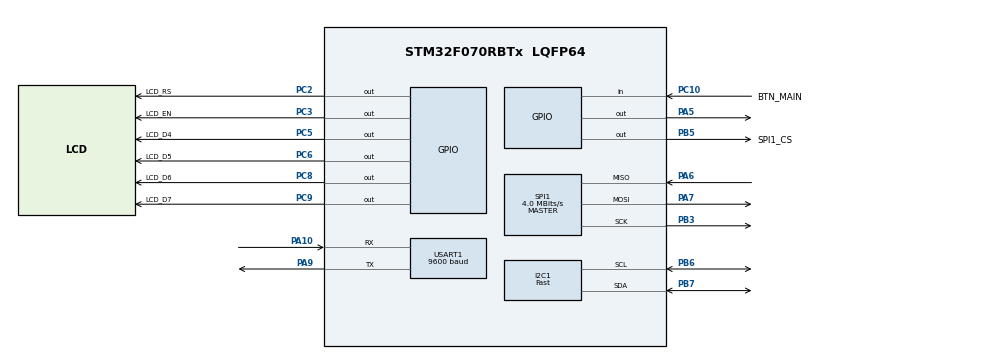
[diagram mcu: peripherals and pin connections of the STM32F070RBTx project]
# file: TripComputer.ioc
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Dma.Request0=USART1_RX
Dma.USART1_RX.0.Direction=DMA_PERIPH_TO_MEMORY
Dma.USART1_RX.0.Instance=DMA1_Channel3
Dma.USART1_RX.0.MemDataAlignment=DMA_MDATAALIGN_BYTE
Dma.USART1_RX.0.MemInc=DMA_MINC_ENABLE
Dma.USART1_RX.0.Mode=DMA_CIRCULAR
Dma.USART1_RX.0.PeriphDataAlignment=DMA_PDATAALIGN_BYTE
Dma.USART1_RX.0.PeriphInc=DMA_PINC_DISABLE
Dma.USART1_RX.0.Priority=DMA_PRIORITY_HIGH
FREERTOS.Tasks01=defaultTask,24,128,StartDefaultTask,Default,NULL,Dynamic,NULL,NULL
FREERTOS.configCHECK_FOR_STACK_OVERFLOW=2
I2C1.I2C_Speed_Mode=I2C_Fast
I2C1.Timing=0x0010020A
Mcu.Family=STM32F0
Mcu.Name=STM32F070RBTx
Mcu.Package=LQFP64
NVIC.DMA1_Channel2_3_IRQn=true\:3\:0\:false\:false\:true\:true\:false\:true\:true
NVIC.TIM1_BRK_UP_TRG_COM_IRQn=true\:3\:0\:false\:false\:true\:false\:false\:true\:true
NVIC.TimeBase=TIM1_BRK_UP_TRG_COM_IRQn
NVIC.TimeBaseIP=TIM1
NVIC.USART1_IRQn=true\:3\:0\:false\:false\:true\:true\:true\:true\:true
PA10.Mode=Asynchronous
PA10.Signal=USART1_RX
PA13.Mode=Serial_Wire
PA13.Signal=SYS_SWDIO
PA14.Mode=Serial_Wire
PA14.Signal=SYS_SWCLK
PA5.Signal=GPIO_Output
PA6.Mode=Full_Duplex_Master
PA6.Signal=SPI1_MISO
PA7.Mode=Full_Duplex_Master
PA7.Signal=SPI1_MOSI
PA9.Mode=Asynchronous
PA9.Signal=USART1_TX
PB3.Mode=Full_Duplex_Master
PB3.Signal=SPI1_SCK
PB5.GPIO_Label=SPI1_CS
PB5.Signal=GPIO_Output
PB6.Mode=I2C
PB6.Signal=I2C1_SCL
PB7.Mode=I2C
PB7.Signal=I2C1_SDA
PC10.GPIO_Label=BTN_MAIN
PC10.GPIO_PuPd=GPIO_PULLUP
PC10.Signal=GPIO_Input
PC2.GPIO_Label=LCD_RS
PC2.Signal=GPIO_Output
PC3.GPIO_Label=LCD_EN
PC3.Signal=GPIO_Output
PC5.GPIO_Label=LCD_D4
PC5.Signal=GPIO_Output
PC6.GPIO_Label=LCD_D5
PC6.Signal=GPIO_Output
PC8.GPIO_Label=LCD_D6
PC8.Signal=GPIO_Output
PC9.GPIO_Label=LCD_D7
PC9.Signal=GPIO_Output
ProjectManager.HeapSize=0x200
ProjectManager.StackSize=0x400
ProjectManager.TargetToolchain=CMake
SPI1.CalculateBaudRate=4.0 MBits/s
SPI1.Direction=SPI_DIRECTION_2LINES
SPI1.Mode=SPI_MODE_MASTER
SPI1.VirtualType=VM_MASTER
USART1.BaudRate=9600
USART1.VirtualMode-Asynchronous=VM_ASYNC
VP_FATFS_VS_Generic.Mode=User_defined
VP_FREERTOS_VS_CMSIS_V2.Mode=CMSIS_V2
VP_SYS_VS_tim1.Mode=TIM1
board=custom

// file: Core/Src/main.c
/* USER CODE BEGIN Header */
/**
  ******************************************************************************
  * @file           : main.c
  * @brief          : Main program body
  ******************************************************************************
  * @attention
  *
  * Copyright (c) 2026 STMicroelectronics.
  * All rights reserved.
  *
  * This software is licensed under terms that can be found in the LICENSE file
  * in the root directory of this software component.
  * If no LICENSE file comes with this software, it is provided AS-IS.
  *
  ******************************************************************************
  */
/* USER CODE END Header */
#include "main.h"
#include "cmsis_os.h"
#include "fatfs.h"

/* USER CODE BEGIN Includes */
#include "App.h"
/* USER CODE END Includes */

I2C_HandleTypeDef hi2c1;

SPI_HandleTypeDef hspi1;

UART_HandleTypeDef huart1;
DMA_HandleTypeDef hdma_usart1_rx;

/* Definitions for defaultTask */
osThreadId_t defaultTaskHandle;
const osThreadAttr_t defaultTask_attributes = {
  .name = "defaultTask",
  .stack_size = 128 * 4,
  .priority = (osPriority_t) osPriorityNormal,
};

void SystemClock_Config(void);
static void MX_GPIO_Init(void);
static void MX_DMA_Init(void);
static void MX_USART1_UART_Init(void);
static void MX_I2C1_Init(void);
static void MX_SPI1_Init(void);
void StartDefaultTask(void *argument);

int main(void)
{

  /* MCU Configuration--------------------------------------------------------*/

  /* Reset of all peripherals, Initializes the Flash interface and the Systick. */
  HAL_Init();

  /* Configure the system clock */
  SystemClock_Config();

  /* Initialize all configured peripherals */
  MX_GPIO_Init();
  MX_DMA_Init();
  MX_USART1_UART_Init();
  MX_I2C1_Init();
  MX_SPI1_Init();
  MX_FATFS_Init();
  /* USER CODE BEGIN 2 */
  App_Main();
  /* USER CODE END 2 */

  /* Init scheduler */
  osKernelInitialize();

  /* Create the thread(s) */
  /* creation of defaultTask */
  defaultTaskHandle = osThreadNew(StartDefaultTask, NULL, &defaultTask_attributes);

  /* Start scheduler */
  osKernelStart();

  /* We should never get here as control is now taken by the scheduler */

  /* Infinite loop */
  while (1)
  {

  }
}

void SystemClock_Config(void)
{
  RCC_OscInitTypeDef RCC_OscInitStruct = {0};
  RCC_ClkInitTypeDef RCC_ClkInitStruct = {0};
  RCC_PeriphCLKInitTypeDef PeriphClkInit = {0};

  /** Initializes the RCC Oscillators according to the specified parameters
  * in the RCC_OscInitTypeDef structure.
  */
  RCC_OscInitStruct.OscillatorType = RCC_OSCILLATORTYPE_HSI;
  RCC_OscInitStruct.HSIState = RCC_HSI_ON;
  RCC_OscInitStruct.HSICalibrationValue = RCC_HSICALIBRATION_DEFAULT;
  RCC_OscInitStruct.PLL.PLLState = RCC_PLL_NONE;
  if (HAL_RCC_OscConfig(&RCC_OscInitStruct) != HAL_OK)
  {
    Error_Handler();
  }

  /** Initializes the CPU, AHB and APB buses clocks
  */
  RCC_ClkInitStruct.ClockType = RCC_CLOCKTYPE_HCLK|RCC_CLOCKTYPE_SYSCLK
                              |RCC_CLOCKTYPE_PCLK1;
  RCC_ClkInitStruct.SYSCLKSource = RCC_SYSCLKSOURCE_HSI;
  RCC_ClkInitStruct.AHBCLKDivider = RCC_SYSCLK_DIV1;
  RCC_ClkInitStruct.APB1CLKDivider = RCC_HCLK_DIV1;

  if (HAL_RCC_ClockConfig(&RCC_ClkInitStruct, FLASH_LATENCY_0) != HAL_OK)
  {
    Error_Handler();
  }
  PeriphClkInit.PeriphClockSelection = RCC_PERIPHCLK_USART1|RCC_PERIPHCLK_I2C1;
  PeriphClkInit.Usart1ClockSelection = RCC_USART1CLKSOURCE_PCLK1;
  PeriphClkInit.I2c1ClockSelection = RCC_I2C1CLKSOURCE_HSI;
  if (HAL_RCCEx_PeriphCLKConfig(&PeriphClkInit) != HAL_OK)
  {
    Error_Handler();
  }
}

static void MX_I2C1_Init(void)
{

  hi2c1.Instance = I2C1;
  hi2c1.Init.Timing = 0x0010020A;
  hi2c1.Init.OwnAddress1 = 0;
  hi2c1.Init.AddressingMode = I2C_ADDRESSINGMODE_7BIT;
  hi2c1.Init.DualAddressMode = I2C_DUALADDRESS_DISABLE;
  hi2c1.Init.OwnAddress2 = 0;
  hi2c1.Init.OwnAddress2Masks = I2C_OA2_NOMASK;
  hi2c1.Init.GeneralCallMode = I2C_GENERALCALL_DISABLE;
  hi2c1.Init.NoStretchMode = I2C_NOSTRETCH_DISABLE;
  if (HAL_I2C_Init(&hi2c1) != HAL_OK)
  {
    Error_Handler();
  }

  /** Configure Analogue filter
  */
  if (HAL_I2CEx_ConfigAnalogFilter(&hi2c1, I2C_ANALOGFILTER_ENABLE) != HAL_OK)
  {
    Error_Handler();
  }

  /** Configure Digital filter
  */
  if (HAL_I2CEx_ConfigDigitalFilter(&hi2c1, 0) != HAL_OK)
  {
    Error_Handler();
  }

}

static void MX_SPI1_Init(void)
{

  /* SPI1 parameter configuration*/
  hspi1.Instance = SPI1;
  hspi1.Init.Mode = SPI_MODE_MASTER;
  hspi1.Init.Direction = SPI_DIRECTION_2LINES;
  hspi1.Init.DataSize = SPI_DATASIZE_8BIT;
  hspi1.Init.CLKPolarity = SPI_POLARITY_LOW;
  hspi1.Init.CLKPhase = SPI_PHASE_1EDGE;
  hspi1.Init.NSS = SPI_NSS_SOFT;
  hspi1.Init.BaudRatePrescaler = SPI_BAUDRATEPRESCALER_32;
  hspi1.Init.FirstBit = SPI_FIRSTBIT_MSB;
  hspi1.Init.TIMode = SPI_TIMODE_DISABLE;
  hspi1.Init.CRCCalculation = SPI_CRCCALCULATION_DISABLE;
  hspi1.Init.CRCPolynomial = 7;
  hspi1.Init.CRCLength = SPI_CRC_LENGTH_DATASIZE;
  hspi1.Init.NSSPMode = SPI_NSS_PULSE_DISABLE;
  if (HAL_SPI_Init(&hspi1) != HAL_OK)
  {
    Error_Handler();
  }

}

static void MX_USART1_UART_Init(void)
{

  huart1.Instance = USART1;
  huart1.Init.BaudRate = 9600;
  huart1.Init.WordLength = UART_WORDLENGTH_8B;
  huart1.Init.StopBits = UART_STOPBITS_1;
  huart1.Init.Parity = UART_PARITY_NONE;
  huart1.Init.Mode = UART_MODE_TX_RX;
  huart1.Init.HwFlowCtl = UART_HWCONTROL_NONE;
  huart1.Init.OverSampling = UART_OVERSAMPLING_16;
  huart1.Init.OneBitSampling = UART_ONE_BIT_SAMPLE_DISABLE;
  huart1.AdvancedInit.AdvFeatureInit = UART_ADVFEATURE_NO_INIT;
  if (HAL_UART_Init(&huart1) != HAL_OK)
  {
    Error_Handler();
  }

}

static void MX_DMA_Init(void)
{

  /* DMA controller clock enable */
  __HAL_RCC_DMA1_CLK_ENABLE();

  /* DMA interrupt init */
  /* DMA1_Channel2_3_IRQn interrupt configuration */
  HAL_NVIC_SetPriority(DMA1_Channel2_3_IRQn, 3, 0);
  HAL_NVIC_EnableIRQ(DMA1_Channel2_3_IRQn);

}

static void MX_GPIO_Init(void)
{
  GPIO_InitTypeDef GPIO_InitStruct = {0};

  /* GPIO Ports Clock Enable */
  __HAL_RCC_GPIOC_CLK_ENABLE();
  __HAL_RCC_GPIOA_CLK_ENABLE();
  __HAL_RCC_GPIOB_CLK_ENABLE();

  /*Configure GPIO pin Output Level */
  HAL_GPIO_WritePin(GPIOC, LCD_RS_Pin|LCD_EN_Pin|LCD_D4_Pin|LCD_D5_Pin
                          |LCD_D6_Pin|LCD_D7_Pin, GPIO_PIN_RESET);

  /*Configure GPIO pin Output Level */
  HAL_GPIO_WritePin(GPIOA, GPIO_PIN_5, GPIO_PIN_RESET);

  /*Configure GPIO pin Output Level */
  HAL_GPIO_WritePin(SPI1_CS_GPIO_Port, SPI1_CS_Pin, GPIO_PIN_RESET);

  /*Configure GPIO pins : LCD_RS_Pin LCD_EN_Pin LCD_D4_Pin LCD_D5_Pin
                           LCD_D6_Pin LCD_D7_Pin */
  GPIO_InitStruct.Pin = LCD_RS_Pin|LCD_EN_Pin|LCD_D4_Pin|LCD_D5_Pin
                          |LCD_D6_Pin|LCD_D7_Pin;
  GPIO_InitStruct.Mode = GPIO_MODE_OUTPUT_PP;
  GPIO_InitStruct.Pull = GPIO_NOPULL;
  GPIO_InitStruct.Speed = GPIO_SPEED_FREQ_LOW;
  HAL_GPIO_Init(GPIOC, &GPIO_InitStruct);

  /*Configure GPIO pin : PA5 */
  GPIO_InitStruct.Pin = GPIO_PIN_5;
  GPIO_InitStruct.Mode = GPIO_MODE_OUTPUT_PP;
  GPIO_InitStruct.Pull = GPIO_NOPULL;
  GPIO_InitStruct.Speed = GPIO_SPEED_FREQ_LOW;
  HAL_GPIO_Init(GPIOA, &GPIO_InitStruct);

  /*Configure GPIO pin : BTN_MAIN_Pin */
  GPIO_InitStruct.Pin = BTN_MAIN_Pin;
  GPIO_InitStruct.Mode = GPIO_MODE_INPUT;
  GPIO_InitStruct.Pull = GPIO_PULLUP;
  HAL_GPIO_Init(BTN_MAIN_GPIO_Port, &GPIO_InitStruct);

  /*Configure GPIO pin : SPI1_CS_Pin */
  GPIO_InitStruct.Pin = SPI1_CS_Pin;
  GPIO_InitStruct.Mode = GPIO_MODE_OUTPUT_PP;
  GPIO_InitStruct.Pull = GPIO_NOPULL;
  GPIO_InitStruct.Speed = GPIO_SPEED_FREQ_LOW;
  HAL_GPIO_Init(SPI1_CS_GPIO_Port, &GPIO_InitStruct);

}

void StartDefaultTask(void *argument)
{
  for(;;)
  {
    osDelay(1);
  }
}

void HAL_TIM_PeriodElapsedCallback(TIM_HandleTypeDef *htim)
{
  if (htim->Instance == TIM1)
  {
    HAL_IncTick();
  }
}

void Error_Handler(void)
{
  __disable_irq();
  while (1)
  {
  }
}
